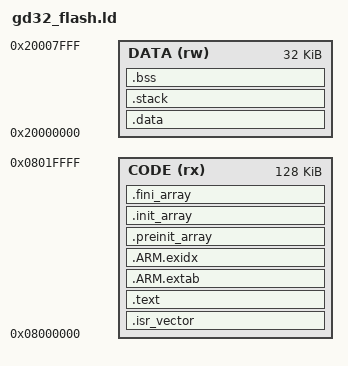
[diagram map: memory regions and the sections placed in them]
/*
 * linker script for GD32F1xx with GNU ld
 *
 * Change Logs:
 * Date           Author           Notes
 */

/* Program Entry, set to mark it as "used" and avoid gc */
MEMORY
{
  CODE (rx) : ORIGIN = 0x08000000, LENGTH = 128K
  DATA (rw) : ORIGIN = 0x20000000, LENGTH = 32K
}
ENTRY(Reset_Handler)
_system_stack_size = 0x200;

SECTIONS
{
  .isr_vector :
  {
    . = ALIGN(4);
    KEEP(*(.isr_vector)) /* Startup code */
    . = ALIGN(4);
  } >CODE

  /* The program code and other data goes into FLASH */
  .text :
  {
    . = ALIGN(4);
    *(.text)           /* .text sections (code) */
    *(.text*)          /* .text* sections (code) */
    *(.rodata)         /* .rodata sections (constants, strings, etc.) */
    *(.rodata*)        /* .rodata* sections (constants, strings, etc.) */
    *(.glue_7)         /* glue arm to thumb code */
    *(.glue_7t)        /* glue thumb to arm code */
    *(.gnu.linkonce.t*)

    KEEP (*(.init))
    KEEP (*(.fini))
    
    /* section information for finsh shell */
    . = ALIGN(4);

    __fsymtab_start = .;
    KEEP(*(FSymTab))
    __fsymtab_end = .;
    . = ALIGN(4);

    __vsymtab_start = .;
    KEEP(*(VSymTab))
    __vsymtab_end = .;
    . = ALIGN(4);

    __rt_init_start = .;
    KEEP(*(SORT(.rti_fn*)))
    __rt_init_end = .;
    . = ALIGN(4);

    _etext = .;
  } >CODE

  .ARM.extab : { 
    *(.ARM.extab* .gnu.linkonce.armextab.*) 
  } >CODE
    
  /* .ARM.exidx is sorted, so has to go in its own output section.  */
  __exidx_start = .;
  .ARM.exidx :
  {
    *(.ARM.exidx* .gnu.linkonce.armexidx.*)
  } > CODE
  __exidx_end = .;

  .preinit_array :
  {
    PROVIDE_HIDDEN (__preinit_array_start = .);
    KEEP (*(.preinit_array*))
    PROVIDE_HIDDEN (__preinit_array_end = .);
  } >CODE

  .init_array :
  {
    PROVIDE_HIDDEN (__init_array_start = .);
    KEEP (*(SORT(.init_array.*)))
    KEEP (*(.init_array*))
    PROVIDE_HIDDEN (__init_array_end = .);
  } >CODE

  .fini_array :
  {
    PROVIDE_HIDDEN (__fini_array_start = .);
    KEEP (*(.fini_array*))
    KEEP (*(SORT(.fini_array.*)))
    PROVIDE_HIDDEN (__fini_array_end = .);
  } >CODE

  /* used by the startup to initialize data */
  _sidata = .;

  /* Initialized data sections goes into RAM, load LMA copy after code */
  .data : AT ( _sidata )
  {
    . = ALIGN(4);
    _sdata = .;        /* create a global symbol at data start */
    
    *(.data)           /* .data sections */
    *(.data*)          /* .data* sections */
    *(.gnu.linkonce.d*)

    . = ALIGN(4);
    _edata = .;        /* define a global symbol at data end */
  } >DATA

  .stack : 
  {
    . = . + _system_stack_size;
    . = ALIGN(4);
    _estack = .;
  } >DATA

  /* Uninitialized data section */
  . = ALIGN(4);
  .bss :
  {
    /* This is used by the startup in order to initialize the .bss secion */
    _sbss = .;         /* define a global symbol at bss start */
    __bss_start__ = _sbss;
    
    *(.bss)
    *(.bss*)
    *(COMMON)

    . = ALIGN(4);
    _ebss = .;         /* define a global symbol at bss end */
    __bss_end__ = _ebss;
  } >DATA

  PROVIDE ( end = _ebss );
  PROVIDE ( _end = _ebss );

  /* Stabs debugging sections.  */
  .stab          0 : { *(.stab) }
  .stabstr       0 : { *(.stabstr) }
  .stab.excl     0 : { *(.stab.excl) }
  .stab.exclstr  0 : { *(.stab.exclstr) }
  .stab.index    0 : { *(.stab.index) }
  .stab.indexstr 0 : { *(.stab.indexstr) }
  .comment       0 : { *(.comment) }
  /* DWARF debug sections.
    * Symbols in the DWARF debugging sections are relative to the beginning
    * of the section so we begin them at 0.  */
  /* DWARF 1 */
  .debug          0 : { *(.debug) }
  .line           0 : { *(.line) }
  /* GNU DWARF 1 extensions */
  .debug_srcinfo  0 : { *(.debug_srcinfo) }
  .debug_sfnames  0 : { *(.debug_sfnames) }
  /* DWARF 1.1 and DWARF 2 */
  .debug_aranges  0 : { *(.debug_aranges) }
  .debug_pubnames 0 : { *(.debug_pubnames) }
  /* DWARF 2 */
  .debug_info     0 : { *(.debug_info .gnu.linkonce.wi.*) }
  .debug_abbrev   0 : { *(.debug_abbrev) }
  .debug_line     0 : { *(.debug_line) }
  .debug_frame    0 : { *(.debug_frame) }
  .debug_str      0 : { *(.debug_str) }
  .debug_loc      0 : { *(.debug_loc) }
  .debug_macinfo  0 : { *(.debug_macinfo) }
  /* SGI/MIPS DWARF 2 extensions */
  .debug_weaknames 0 : { *(.debug_weaknames) }
  .debug_funcnames 0 : { *(.debug_funcnames) }
  .debug_typenames 0 : { *(.debug_typenames) }
  .debug_varnames  0 : { *(.debug_varnames) }
}
